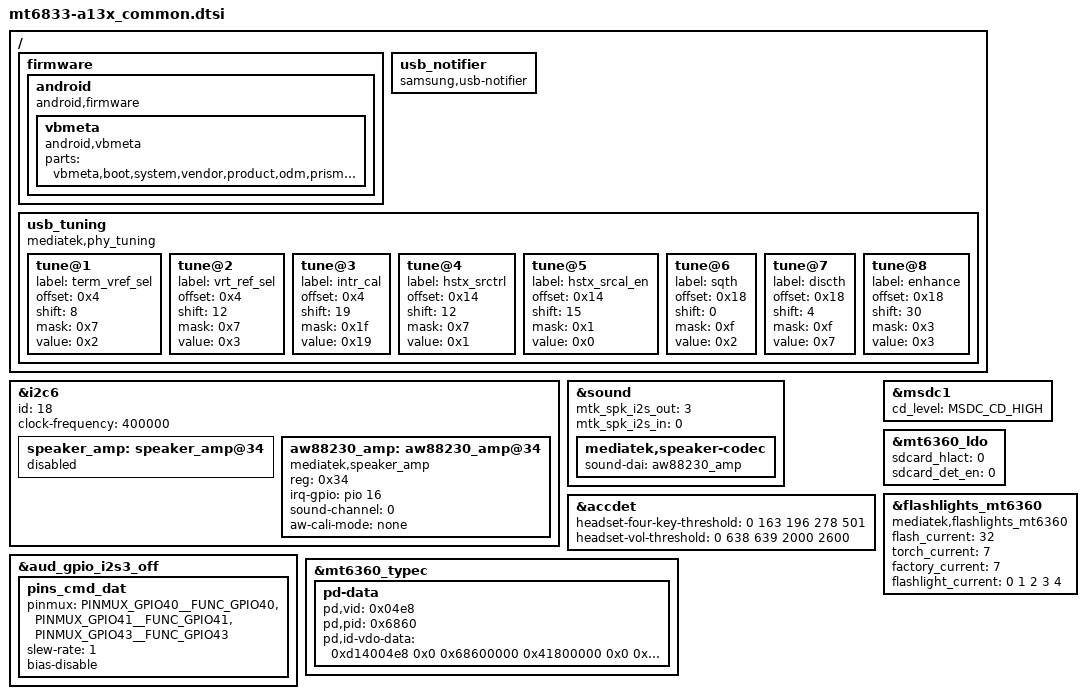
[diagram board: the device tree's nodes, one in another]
/* Generated by Samsung for MTK vendor board
 * If these files should be changed, then please make a sync with MTK
*/
#include <dt-bindings/mmc/mt6833-msdc.h>

/* Add Samsung configuration over here */
/ {
	fragment@model {
		target-path = "/";
		__overlay__ {
			firmware {
				android {
					compatible = "android,firmware";
					vbmeta {
						compatible = "android,vbmeta";
						parts = "vbmeta,boot,system,vendor,product,odm,prism,optics,vbmeta_system,recovery,lk,tee1";
					};
				};
			};

			usb_notifier {
				compatible = "samsung,usb-notifier";
			};

			usb_tuning: usb_tuning {
				compatible = "mediatek,phy_tuning";

				tune@1 {
					label = "term_vref_sel";
					offset = <0x4>;
					shift = <8>;
					mask = <0x7>;
					value = <0x2>;
				};
				tune@2 {
					label = "vrt_ref_sel";
					offset = <0x4>;
					shift = <12>;
					mask = <0x7>;
					value = <0x3>;
				};
				tune@3 {
					label = "intr_cal";
					offset = <0x4>;
					shift = <19>;
					mask = <0x1f>;
					value = <0x19>;
				};
				tune@4 {
					label = "hstx_srctrl";
					offset = <0x14>;
					shift = <12>;
					mask = <0x7>;
					value = <0x1>;
				};
				tune@5 {
					label = "hstx_srcal_en";
					offset = <0x14>;
					shift = <15>;
					mask = <0x1>;
					value = <0x0>;
				};
				tune@6 {
					label = "sqth";
					offset = <0x18>;
					shift = <0>;
					mask = <0xf>;
					value = <0x2>;
				};
				tune@7 {
					label = "discth";
					offset = <0x18>;
					shift = <4>;
					mask = <0xf>;
					value = <0x7>;
				};
				tune@8 {
					label = "enhance";
					offset = <0x18>;
					shift = <30>;
					mask = <0x3>;
					value = <0x3>;
				};
			};
		};
	};
};

&i2c6 {
	speaker_amp: speaker_amp@34 {
		status = "disabled";
	};
};

&i2c6 {
	status = "okay";
	id = <18>;
	clock-frequency = <400000>;
	#address-cells = <1>;
	#size-cells = <0>;

	aw88230_amp: aw88230_amp@34 {
		compatible = "mediatek,speaker_amp";
		#sound-dai-cells = <0>;
		reg = <0x34>;
		irq-gpio = <&pio 16 0>;
		sound-channel = <0>;
		aw-cali-mode = "none";
		status = "okay";
	};
};

&sound {
	mtk_spk_i2s_out = <3>;
	mtk_spk_i2s_in = <0>;
	mediatek,speaker-codec {
		sound-dai = <&aw88230_amp>;
	};
};

/* accdet start */
&accdet {
	headset-four-key-threshold = <0 163 196 278 501>;
	headset-vol-threshold = <0 638 639 2000 2600>;
};
/* accdet end */

/* I2S gpio configuration */
&aud_gpio_i2s3_off {
	pins_cmd_dat {
		pinmux = <PINMUX_GPIO40__FUNC_GPIO40>,
			 <PINMUX_GPIO41__FUNC_GPIO41>,
			 <PINMUX_GPIO43__FUNC_GPIO43>;
		slew-rate = <1>;
		bias-disable;
	};
};

&msdc1 {
	cd_level = /bits/ 8 <MSDC_CD_HIGH>;
};

&mt6360_ldo {
	sdcard_hlact = <0>;
	sdcard_det_en = <0>;
};

&flashlights_mt6360 {
	compatible = "mediatek,flashlights_mt6360";
	flash_current = <32>;
	torch_current = <7>;
	factory_current = <7>;
	flashlight_current = <0 1 2 3 4>;
};

&mt6360_typec {
	pd-data {
		pd,vid = <0x04e8>;
		pd,pid = <0x6860>;
		pd,id-vdo-data = <0xd14004e8 0x0 0x68600000
				 0x41800000 0x0 0x21800000>;
	};
};
